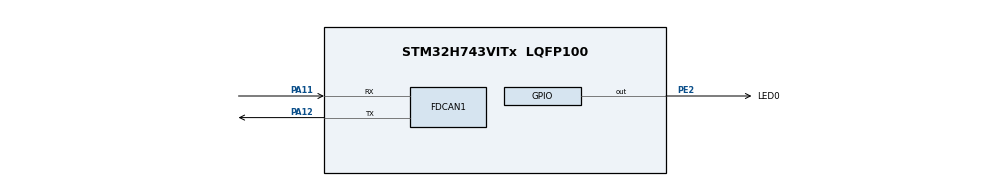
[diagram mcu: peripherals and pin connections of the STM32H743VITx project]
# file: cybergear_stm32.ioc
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FDCAN1.AutoRetransmission=ENABLE
FDCAN1.DataSyncJumpWidth=2
FDCAN1.DataTimeSeg1=7
FDCAN1.DataTimeSeg2=2
FDCAN1.ExtFiltersNbr=1
FDCAN1.FrameFormat=FDCAN_FRAME_FD_BRS
FDCAN1.NominalSyncJumpWidth=16
FDCAN1.NominalTimeSeg1=63
FDCAN1.NominalTimeSeg2=16
FDCAN1.RxFifo0ElmtSize=FDCAN_DATA_BYTES_64
FDCAN1.RxFifo0ElmtsNbr=1
FDCAN1.StdFiltersNbr=0
FDCAN1.TxElmtSize=FDCAN_DATA_BYTES_64
FDCAN1.TxFifoQueueElmtsNbr=10
Mcu.Family=STM32H7
Mcu.Name=STM32H743VITx
Mcu.Package=LQFP100
NVIC.FDCAN1_IT0_IRQn=true\:0\:0\:false\:false\:true\:true\:true
NVIC.PriorityGroup=NVIC_PRIORITYGROUP_4
NVIC.TIM8_BRK_TIM12_IRQn=true\:15\:0\:false\:false\:true\:false\:true
NVIC.TimeBase=TIM8_BRK_TIM12_IRQn
NVIC.TimeBaseIP=TIM12
PA11.Mode=FDCAN_Activate
PA11.Signal=FDCAN1_RX
PA12.Mode=FDCAN_Activate
PA12.Signal=FDCAN1_TX
PA13\ (JTMS/SWDIO).Mode=Serial_Wire
PA13\ (JTMS/SWDIO).Signal=DEBUG_JTMS-SWDIO
PA14\ (JTCK/SWCLK).Mode=Serial_Wire
PA14\ (JTCK/SWCLK).Signal=DEBUG_JTCK-SWCLK
PE2.GPIO_Label=LED0
PE2.Signal=GPIO_Output
PH0-OSC_IN\ (PH0).Mode=HSE-External-Oscillator
PH0-OSC_IN\ (PH0).Signal=RCC_OSC_IN
PH1-OSC_OUT\ (PH1).Mode=HSE-External-Oscillator
PH1-OSC_OUT\ (PH1).Signal=RCC_OSC_OUT
ProjectManager.HeapSize=0x200
ProjectManager.StackSize=0x400
ProjectManager.TargetToolchain=STM32CubeIDE
RCC.ADCFreq_Value=400000000
RCC.APB1Freq_Value=100000000
RCC.APB2Freq_Value=100000000
RCC.APB3Freq_Value=100000000
RCC.APB4Freq_Value=100000000
RCC.CortexFreq_Value=400000000
RCC.D1PPRE=RCC_APB3_DIV2
RCC.D2PPRE1=RCC_APB1_DIV2
RCC.D2PPRE2=RCC_APB2_DIV2
RCC.D3PPRE=RCC_APB4_DIV2
RCC.DIVM1=1
RCC.DIVM2=1
RCC.DIVM3=1
RCC.DIVN1=100
RCC.DIVN2=100
RCC.DIVN3=100
RCC.DIVQ1=8
RCC.DIVQ2=10
RCC.FDCANCLockSelection=RCC_FDCANCLKSOURCE_PLL2
RCC.HCLKFreq_Value=200000000
RCC.HPRE=RCC_HCLK_DIV2
RCC.HSE_VALUE=8000000
RCC.PLLFRACN=0
RCC.PLLSourceVirtual=RCC_PLLSOURCE_HSE
RCC.SYSCLKFreq_VALUE=400000000
RCC.SYSCLKSource=RCC_SYSCLKSOURCE_PLLCLK
RCC.USBFreq_Value=100000000
VP_SYS_VS_tim12.Mode=TIM12
board=custom

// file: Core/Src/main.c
/* USER CODE BEGIN Header */
/**
  ******************************************************************************
  * @file           : main.c
  * @brief          : Main program body
  ******************************************************************************
  * @attention
  *
  * Copyright (c) 2024 STMicroelectronics.
  * All rights reserved.
  *
  * This software is licensed under terms that can be found in the LICENSE file
  * in the root directory of this software component.
  * If no LICENSE file comes with this software, it is provided AS-IS.
  *
  ******************************************************************************
  */
/* USER CODE END Header */
#include "main.h"

/* USER CODE BEGIN Includes */
#include "cybergear/cybergear_can_interface_stm32.hh"
#include "cybergear/cybergear_driver.hh"
/* USER CODE END Includes */

FDCAN_HandleTypeDef hfdcan1;

void SystemClock_Config(void);
static void MX_GPIO_Init(void);
static void MX_FDCAN1_Init(void);

int main(void)
{

  /* MCU Configuration--------------------------------------------------------*/

  /* Reset of all peripherals, Initializes the Flash interface and the Systick. */
  HAL_Init();

  /* Configure the system clock */
  SystemClock_Config();

  /* Initialize all configured peripherals */
  MX_GPIO_Init();
  MX_FDCAN1_Init();
  /* USER CODE BEGIN 2 */
  CybergearCanInterfaceStm32 cybergear_can_interface_;
  cybergear_can_interface_.init(&hfdcan1);
  CybergearDriver driver1_(0x000, 0x7F);
  CybergearDriver driver2_(0x000, 0x7E);
  driver1_.init(&cybergear_can_interface_);
  driver2_.init(&cybergear_can_interface_);

  driver1_.reset_motor();
  driver1_.set_mech_position_to_zero();
  driver1_.enable_motor();
  driver1_.set_run_mode(CMD_CONTROL);

  driver2_.reset_motor();
  driver2_.set_mech_position_to_zero();
  driver2_.enable_motor();
  driver2_.set_run_mode(CMD_CONTROL);
  /* USER CODE END 2 */

  /* Infinite loop */
  /* USER CODE BEGIN WHILE */
  while (1)
  {
    HAL_GPIO_TogglePin(LED0_GPIO_Port, LED0_Pin);

    driver1_.motor_control(0.0, 0.1, 0.0, 15, 1);
    HAL_Delay(500);
    driver2_.motor_control(0.0, 0.1, 0.0, 15, 1);
    HAL_Delay(500);
    driver1_.motor_control(1.0, 0.1, 0.0, 15, 1);
    HAL_Delay(500);
    driver2_.motor_control(1.0, 0.1, 0.0, 15, 1);
    HAL_Delay(500);

    /* USER CODE END WHILE */

  }
}

void SystemClock_Config(void)
{
  RCC_OscInitTypeDef RCC_OscInitStruct = {0};
  RCC_ClkInitTypeDef RCC_ClkInitStruct = {0};

  /** Supply configuration update enable
  */
  HAL_PWREx_ConfigSupply(PWR_LDO_SUPPLY);
  /** Configure the main internal regulator output voltage
  */
  __HAL_PWR_VOLTAGESCALING_CONFIG(PWR_REGULATOR_VOLTAGE_SCALE1);

  while(!__HAL_PWR_GET_FLAG(PWR_FLAG_VOSRDY)) {}
  /** Macro to configure the PLL clock source
  */
  __HAL_RCC_PLL_PLLSOURCE_CONFIG(RCC_PLLSOURCE_HSE);
  /** Initializes the RCC Oscillators according to the specified parameters
  * in the RCC_OscInitTypeDef structure.
  */
  RCC_OscInitStruct.OscillatorType = RCC_OSCILLATORTYPE_HSE;
  RCC_OscInitStruct.HSEState = RCC_HSE_ON;
  RCC_OscInitStruct.PLL.PLLState = RCC_PLL_ON;
  RCC_OscInitStruct.PLL.PLLSource = RCC_PLLSOURCE_HSE;
  RCC_OscInitStruct.PLL.PLLM = 1;
  RCC_OscInitStruct.PLL.PLLN = 100;
  RCC_OscInitStruct.PLL.PLLP = 2;
  RCC_OscInitStruct.PLL.PLLQ = 8;
  RCC_OscInitStruct.PLL.PLLR = 2;
  RCC_OscInitStruct.PLL.PLLRGE = RCC_PLL1VCIRANGE_3;
  RCC_OscInitStruct.PLL.PLLVCOSEL = RCC_PLL1VCOWIDE;
  RCC_OscInitStruct.PLL.PLLFRACN = 0;
  if (HAL_RCC_OscConfig(&RCC_OscInitStruct) != HAL_OK)
  {
    Error_Handler();
  }
  /** Initializes the CPU, AHB and APB buses clocks
  */
  RCC_ClkInitStruct.ClockType = RCC_CLOCKTYPE_HCLK|RCC_CLOCKTYPE_SYSCLK
                              |RCC_CLOCKTYPE_PCLK1|RCC_CLOCKTYPE_PCLK2
                              |RCC_CLOCKTYPE_D3PCLK1|RCC_CLOCKTYPE_D1PCLK1;
  RCC_ClkInitStruct.SYSCLKSource = RCC_SYSCLKSOURCE_PLLCLK;
  RCC_ClkInitStruct.SYSCLKDivider = RCC_SYSCLK_DIV1;
  RCC_ClkInitStruct.AHBCLKDivider = RCC_HCLK_DIV2;
  RCC_ClkInitStruct.APB3CLKDivider = RCC_APB3_DIV2;
  RCC_ClkInitStruct.APB1CLKDivider = RCC_APB1_DIV2;
  RCC_ClkInitStruct.APB2CLKDivider = RCC_APB2_DIV2;
  RCC_ClkInitStruct.APB4CLKDivider = RCC_APB4_DIV2;

  if (HAL_RCC_ClockConfig(&RCC_ClkInitStruct, FLASH_LATENCY_2) != HAL_OK)
  {
    Error_Handler();
  }
}

static void MX_FDCAN1_Init(void)
{

  hfdcan1.Instance = FDCAN1;
  hfdcan1.Init.FrameFormat = FDCAN_FRAME_FD_BRS;
  hfdcan1.Init.Mode = FDCAN_MODE_NORMAL;
  hfdcan1.Init.AutoRetransmission = ENABLE;
  hfdcan1.Init.TransmitPause = DISABLE;
  hfdcan1.Init.ProtocolException = DISABLE;
  hfdcan1.Init.NominalPrescaler = 1;
  hfdcan1.Init.NominalSyncJumpWidth = 16;
  hfdcan1.Init.NominalTimeSeg1 = 63;
  hfdcan1.Init.NominalTimeSeg2 = 16;
  hfdcan1.Init.DataPrescaler = 1;
  hfdcan1.Init.DataSyncJumpWidth = 2;
  hfdcan1.Init.DataTimeSeg1 = 7;
  hfdcan1.Init.DataTimeSeg2 = 2;
  hfdcan1.Init.MessageRAMOffset = 0;
  hfdcan1.Init.StdFiltersNbr = 0;
  hfdcan1.Init.ExtFiltersNbr = 1;
  hfdcan1.Init.RxFifo0ElmtsNbr = 1;
  hfdcan1.Init.RxFifo0ElmtSize = FDCAN_DATA_BYTES_64;
  hfdcan1.Init.RxFifo1ElmtsNbr = 0;
  hfdcan1.Init.RxFifo1ElmtSize = FDCAN_DATA_BYTES_8;
  hfdcan1.Init.RxBuffersNbr = 0;
  hfdcan1.Init.RxBufferSize = FDCAN_DATA_BYTES_8;
  hfdcan1.Init.TxEventsNbr = 0;
  hfdcan1.Init.TxBuffersNbr = 0;
  hfdcan1.Init.TxFifoQueueElmtsNbr = 10;
  hfdcan1.Init.TxFifoQueueMode = FDCAN_TX_FIFO_OPERATION;
  hfdcan1.Init.TxElmtSize = FDCAN_DATA_BYTES_64;
  if (HAL_FDCAN_Init(&hfdcan1) != HAL_OK)
  {
    Error_Handler();
  }

}

static void MX_GPIO_Init(void)
{
  GPIO_InitTypeDef GPIO_InitStruct = {0};

  /* GPIO Ports Clock Enable */
  __HAL_RCC_GPIOE_CLK_ENABLE();
  __HAL_RCC_GPIOH_CLK_ENABLE();
  __HAL_RCC_GPIOA_CLK_ENABLE();

  /*Configure GPIO pin Output Level */
  HAL_GPIO_WritePin(LED0_GPIO_Port, LED0_Pin, GPIO_PIN_RESET);

  /*Configure GPIO pin : LED0_Pin */
  GPIO_InitStruct.Pin = LED0_Pin;
  GPIO_InitStruct.Mode = GPIO_MODE_OUTPUT_PP;
  GPIO_InitStruct.Pull = GPIO_NOPULL;
  GPIO_InitStruct.Speed = GPIO_SPEED_FREQ_LOW;
  HAL_GPIO_Init(LED0_GPIO_Port, &GPIO_InitStruct);

}

void HAL_TIM_PeriodElapsedCallback(TIM_HandleTypeDef *htim)
{
  if (htim->Instance == TIM12) {
    HAL_IncTick();
  }
}

void Error_Handler(void)
{
  __disable_irq();
  while (1)
  {
  }
}
